# RZT2ME register map
Vendor: Renesas Electronics Corporation; Series: RZT; File version: 1.00.00
CPU: other r0p0, little endian, MPU, no FPU, VTOR, 4 interrupt priority bits, 624 interrupts
Registers are 32-bit, read-write, reset 0x0 unless marked. A register's access mark holds for its fields unless they carry their own. Offsets are from the block's base; [hi:lo] are bit positions; {n}, {i} and the like mark numbered series; 'fields as' and 'values as' point back to an identical list.

## SYSRAM0 — System SRAM 0
Base 0x81040000
Same registers: SYSRAM1 0x81041000, SYSRAM2 0x81042000, SYSRAM3 0x81043000
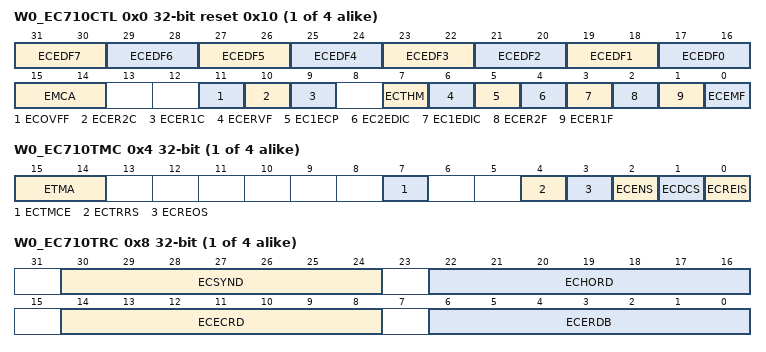
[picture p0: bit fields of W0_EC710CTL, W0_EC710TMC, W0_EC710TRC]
{0x0+0x40*i} W{i}_EC710CTL (i=0..3) reset 0x10 — ECC Control Register {i}
  [2n+17:2n+16] ECEDF{n} ro (n=1..7) — ECC Error Address Capture Flag m (m = {n})
  [17:16] ECEDF0 ro — ECC Error Address Capture Flag m (m = 0)
    0=ECC error address is not captured in Wn_EC710EADm; 1=1-bit ECC error address is captured in Wn_EC710EADm; 2=2-bit ECC error address is captured in Wn_EC710EADm
  [15:14] EMCA — Access Control to ECC Mode Selection
    1=Writing is enabled; other=Others (Writing is disabled)
  [11] ECOVFF ro — ECC Error Address Capture Overflow Flag
    0=ECC error address capture overflow has not occurred; 1=ECC error address capture overflow has occurred
  [10] ECER2C — 2-Bit ECC Error Detection Clear
  [9] ECER1C — 1-Bit ECC Error Detection Clear
  [7] ECTHM — ECC Function Through Mode Enable
    0=Disables Through mode; 1=Enables Through mode. No effect on encoder. Decoder does not determine the error and does not perform error correction.
  [6] ECERVF — ECC Error Determination Enable
    0=The error determination is disabled; 1=The error determination is enabled. The ECC function according to EC1EDIC, EC2EDIC, and EC1ECP bits are enabled.
  [5] EC1ECP — 1-Bit ECC Error Correction Enable
    0=Error correction is performed on detection of a 1-bit ECC error; 1=Error correction is not performed on detection of a 1-bit ECC error
  [4] EC2EDIC — 2-Bit ECC Error Detection Interrupt Control
    0=Disables to output an interrupt signal; 1=Enables to output an interrupt signal
  [3] EC1EDIC — 1-Bit ECC Error Detection Interrupt Control
    values as EC2EDIC
  [2] ECER2F ro — 2-Bit ECC Error Detection Flag
    0=2-bit error has not occurred; 1=2-bit error has occurred
  [1] ECER1F ro — 1-Bit ECC Error Detection/Correction Flag
    0=1-bit error has not occurred; 1=1-bit error has occurred
  [0] ECEMF ro — ECC Error Indicate Flag
    0=No error is detected in the current read data; 1=An error is detected in the current read data
{0x4+0x40*i} W{i}_EC710TMC (i=0..3) — ECC Test Mode Control Register {i}
  [15:14] ETMA — ECTMCE Write Enable
    2=Writing is enabled; other=Others (Writing is disabled)
  [7] ECTMCE — Test Mode Enable
    0=Disables access to the test mode register and its bits; 1=Enables access to the test mode register and its bits
  [4] ECTRRS — RAM Read Test Mode Select
    0=Read value is the written value for the Wn_EC710TED register and the Wn_EC710TRC.ECERDB[6:0] bits; 1=Read value of Wn_EC710TED register is 32-bit output data from RAM and read value of the Wn_EC710TRC.ECERDB[6:0] bits is 7 redundancy bits input to RAM
  [3] ECREOS — ECC Redundancy Bit Output Data Select
    0=The encoded result of the encoder is output; 1=The value of the ECERDB[6:0] bits in the Wn_EC710TRC register is output
  [2] ECENS — ECC Encode Input Select
    0=Data input to RAM is selected; 1=The value of the Wn_EC710TED register is selected
  [1] ECDCS — ECC Decode Input Select
    0=RAM output data is input to the decoder; 1=The value of the Wn_EC710TED register is input to the decoder
  [0] ECREIS — ECC Redundancy Bit Input Data Select
    0=ECC data read from RAM is input to the decoder; 1=The value of the ECERDB[6:0] bits is input to the decoder
{0x8+0x40*i} W{i}_EC710TRC (i=0..3) — ECC Redundancy Bit Data Control Test Register {i}
  [30:24] ECSYND ro — ECC Decode Syndrome Register
  [22:16] ECHORD ro — ECC 7-Redundancy-Bit Data Retain Test Register
  [14:8] ECECRD ro — ECC Encode Test Register
  [6:0] ECERDB — ECC Redundancy Bit Input/Output Substitute Buffer Register
{0xC+0x40*i} W{i}_EC710TED (i=0..3) — ECC Encode/Decode Input/Output Switchover Test Register {i}
  [31:0] ECEDB — 32-Bit Data Test Register for ECC Encode/Decode
{0x10+4i} W0_EC710EAD{i} (i=0..7) ro — ECC Error Address {i} Register 0
  [14:0] ECEAD — Bit Error Address
{0x50+4i} W1_EC710EAD{i} (i=0..7) ro — ECC Error Address {i} Register 1
  [14:0] ECEAD — Bit Error Address
{0x90+4i} W2_EC710EAD{i} (i=0..7) ro — ECC Error Address {i} Register 2
  [14:0] ECEAD — Bit Error Address
{0xD0+4i} W3_EC710EAD{i} (i=0..7) ro — ECC Error Address {i} Register 3
  [14:0] ECEAD — Bit Error Address
